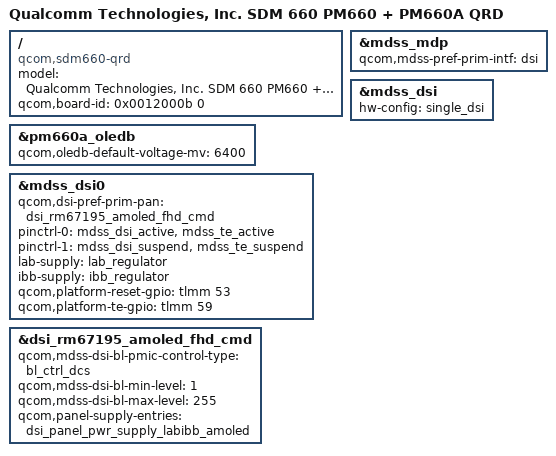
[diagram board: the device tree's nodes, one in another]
/dts-v1/;
/plugin/;

#include <dt-bindings/clock/qcom,cpu-osm.h>
#include <dt-bindings/clock/qcom,rpmcc.h>
#include <dt-bindings/clock/qcom,mmcc-sdm660.h>
#include <dt-bindings/regulator/qcom,rpm-smd-regulator.h>
#include <dt-bindings/interrupt-controller/arm-gic.h>

#include "sdm660-qrd.dtsi"
#include "msm-pm660a.dtsi"

/ {
	model = "Qualcomm Technologies, Inc. SDM 660 PM660 + PM660A QRD";
	compatible = "qcom,sdm660-qrd", "qcom,sdm660", "qcom,qrd";
	qcom,board-id = <0x0012000b 0>;
};

&pm660a_oledb {
	status = "okay";
	qcom,oledb-default-voltage-mv = <6400>;
};

&mdss_mdp {
	qcom,mdss-pref-prim-intf = "dsi";
};

&mdss_dsi {
	hw-config = "single_dsi";
};

&mdss_dsi0 {
	qcom,dsi-pref-prim-pan = <&dsi_rm67195_amoled_fhd_cmd>;
	pinctrl-names = "mdss_default", "mdss_sleep";
	pinctrl-0 = <&mdss_dsi_active &mdss_te_active>;
	pinctrl-1 = <&mdss_dsi_suspend &mdss_te_suspend>;
	lab-supply = <&lab_regulator>;
	ibb-supply = <&ibb_regulator>;
	qcom,platform-reset-gpio = <&tlmm 53 0>;
	qcom,platform-te-gpio = <&tlmm 59 0>;
};

&dsi_rm67195_amoled_fhd_cmd {
	qcom,mdss-dsi-bl-pmic-control-type = "bl_ctrl_dcs";
	qcom,mdss-dsi-bl-min-level = <1>;
	qcom,mdss-dsi-bl-max-level = <255>;
	qcom,panel-supply-entries = <&dsi_panel_pwr_supply_labibb_amoled>;
};
